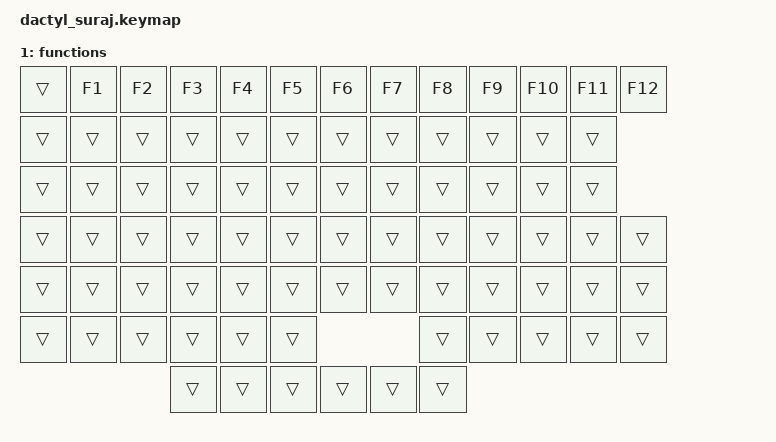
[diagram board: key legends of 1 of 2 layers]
#include <behaviors.dtsi>
#include <dt-bindings/zmk/keys.h>

/ {
	chosen {
        zmk,kscan = &kscan0;
        zmk,physical-layout = &default_layout;
    };
	
	
    keymap {
        compatible = "zmk,keymap";

        main {
            bindings = <
&kp ESC    &kp N1   &kp N2    &kp N3     &kp N4          &kp N5       &kp N6     &kp N7  &kp N8     &kp N9     &kp N0    &kp BSPC  &kp DEL
&kp TAB    &kp Q    &kp W     &kp E      &kp R           &kp T        &kp Y      &kp U   &kp I      &kp O      &kp P     &kp RET
&kp CAPS   &kp A    &kp S     &kp D      &kp F           &kp G        &kp H      &kp J   &kp K      &kp L      &kp FSLH  &kp LBKT  &kp RBKT
&kp LSHFT  &kp Z    &kp X     &kp C      &kp V           &kp B        &kp N      &kp M   &kp COMMA  &kp DOT    &kp SEMI  &kp UP    &kp RSHFT
&kp LCTRL  &kp SQT  &kp BSLH  &kp LEFT_WIN  &mo 1     &kp GRAVE                       &kp MINUS  &kp EQUAL  &kp LEFT  &kp DOWN  &kp RIGHT
                              &kp HASH      &kp LALT  &kp SPACE    &kp SPACE  &kp RALT &kp RCTRL
            >;
        };

        functions {
            bindings = <
&trans  &kp F1  &kp F2  &kp F3  &kp F4  &kp F5    &kp F6  &kp F7  &kp F8  &kp F9  &kp F10  &kp F11  &kp F12
&trans  &trans  &trans  &trans  &trans  &trans    &trans  &trans  &trans  &trans  &trans   &trans
&trans  &trans  &trans  &trans  &trans  &trans    &trans  &trans  &trans  &trans  &trans   &trans
&trans  &trans  &trans  &trans  &trans  &trans    &trans  &trans  &trans  &trans  &trans   &trans   &trans
&trans  &trans  &trans  &trans  &trans  &trans    &trans  &trans  &trans  &trans  &trans   &trans   &trans
&trans  &trans  &trans  &trans  &trans  &trans                    &trans  &trans  &trans   &trans   &trans
                        &trans  &trans  &trans    &trans  &trans  &trans
            >;
        };
    };
};
